# MSP430F155 register map
Vendor: msp430gen; File version: v0.4.0-18-g1912f3a
Registers are 8-bit, read-write, reset 0x0 unless marked. A register's access mark holds for its fields unless they carry their own. Offsets are from the block's base; [hi:lo] are bit positions; {n}, {i} and the like mark numbered series.

## SUPPLY_VOLTAGE_SUPERVISOR
Base 0x00000054
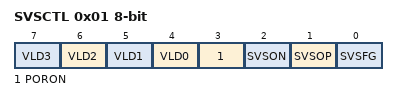
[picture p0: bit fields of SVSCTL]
0x01 SVSCTL — SVS Control
  [n+4] VLD{n} (n=0..3)
  [3] PORON — Enable POR Generation if Low Voltage
  [2] SVSON — Switches the SVS on/off
  [1] SVSOP — SVS output (read only)
  [0] SVSFG — SVS Flag

## SYSTEM_CLOCK
Base 0x00000056
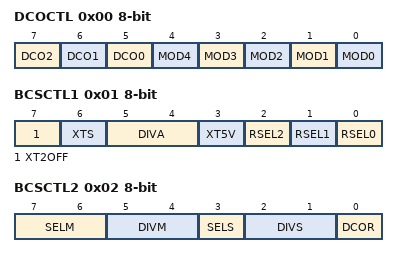
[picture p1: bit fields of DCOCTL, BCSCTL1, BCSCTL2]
0x00 DCOCTL — DCO Clock Frequency Control
  [7] DCO2 — DCO Select Bit 2
  [6] DCO1 — DCO Select Bit 1
  [5] DCO0 — DCO Select Bit 0
  [n] MOD{n} (n=0..4) — Modulation Bit {n}
0x01 BCSCTL1 — Basic Clock System Control 1
  [7] XT2OFF — Enable XT2CLK
  [6] XTS — LFXTCLK 0:Low Freq. / 1: High Freq.
  [5:4] DIVA — ACLK Divider 0
    0=ACLK Divider 0: /1; 1=ACLK Divider 1: /2; 2=ACLK Divider 2: /4; 3=ACLK Divider 3: /8
  [3] XT5V — XT5V should always be reset
  [2] RSEL2 — Range Select Bit 2
  [1] RSEL1 — Range Select Bit 1
  [0] RSEL0 — Range Select Bit 0
0x02 BCSCTL2 — Basic Clock System Control 2
  [7:6] SELM — MCLK Source Select 0
    0=MCLK Source Select 0: DCOCLK; 1=MCLK Source Select 1: DCOCLK; 2=MCLK Source Select 2: XT2CLK/LFXTCLK; 3=MCLK Source Select 3: LFXTCLK
  [5:4] DIVM — MCLK Divider 0
    0=MCLK Divider 0: /1; 1=MCLK Divider 1: /2; 2=MCLK Divider 2: /4; 3=MCLK Divider 3: /8
  [3] SELS — SMCLK Source Select 0:DCOCLK / 1:XT2CLK/LFXTCLK
  [2:1] DIVS — SMCLK Divider 0
    0=SMCLK Divider 0: /1; 1=SMCLK Divider 1: /2; 2=SMCLK Divider 2: /4; 3=SMCLK Divider 3: /8
  [0] DCOR — Enable External Resistor : 1

## COMPARATOR_A
Base 0x00000058
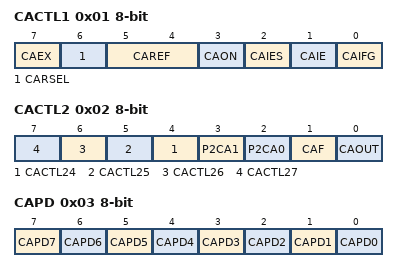
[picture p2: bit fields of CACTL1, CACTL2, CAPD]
0x01 CACTL1 — Comparator A Control 1
  [7] CAEX — Comp. A Exchange Inputs
  [6] CARSEL — Comp. A Internal Reference Enable
  [5:4] CAREF — Comp. A Internal Reference Select 0
    0=Comp. A Int. Ref. Select 0 : Off; 1=Comp. A Int. Ref. Select 1 : 0.25*Vcc; 2=Comp. A Int. Ref. Select 2 : 0.5*Vcc; 3=Comp. A Int. Ref. Select 3 : Vt
  [3] CAON — Comp. A enable
  [2] CAIES — Comp. A Int. Edge Select: 0:rising / 1:falling
  [1] CAIE — Comp. A Interrupt Enable
  [0] CAIFG — Comp. A Interrupt Flag
0x02 CACTL2 — Comparator A Control 2
  [n-20] CACTL{n} (n=24..27)
  [3] P2CA1 — Comp. A Connect External Signal to CA1 : 1
  [2] P2CA0 — Comp. A Connect External Signal to CA0 : 1
  [1] CAF — Comp. A Enable Output Filter
  [0] CAOUT — Comp. A Output
0x03 CAPD — Comparator A Port Disable
  [7] CAPD7 — Comp. A Disable Input Buffer of Port Register .7
  [6] CAPD6 — Comp. A Disable Input Buffer of Port Register .6
  [5] CAPD5 — Comp. A Disable Input Buffer of Port Register .5
  [4] CAPD4 — Comp. A Disable Input Buffer of Port Register .4
  [3] CAPD3 — Comp. A Disable Input Buffer of Port Register .3
  [2] CAPD2 — Comp. A Disable Input Buffer of Port Register .2
  [1] CAPD1 — Comp. A Disable Input Buffer of Port Register .1
  [0] CAPD0 — Comp. A Disable Input Buffer of Port Register .0

## USART_0_UART_SPI_MODE
Base 0x00000070
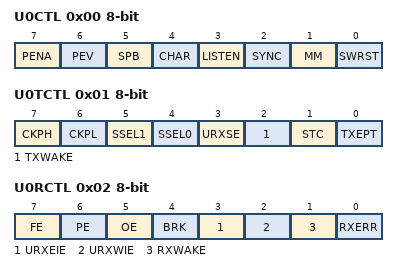
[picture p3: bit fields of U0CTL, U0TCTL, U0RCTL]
0x00 U0CTL — USART 0 Control
  [7] PENA — Parity enable
  [6] PEV — Parity 0:odd / 1:even
  [5] SPB — Stop Bits 0:one / 1: two
  [4] CHAR — Data 0:7-bits / 1:8-bits
  [3] LISTEN — Listen mode
  [2] SYNC — UART / SPI mode
  [1] MM — Master Mode off/on
  [0] SWRST — USART Software Reset
0x01 U0TCTL — USART 0 Transmit Control
  [7] CKPH — SPI: Clock Phase
  [6] CKPL — Clock Polarity
  [5] SSEL1 — Clock Source Select 1
  [4] SSEL0 — Clock Source Select 0
  [3] URXSE — Receive Start edge select
  [2] TXWAKE — TX Wake up mode
  [1] STC — SPI: STC enable 0:on / 1:off
  [0] TXEPT — TX Buffer empty
0x02 U0RCTL — USART 0 Receive Control
  [7] FE — Frame Error
  [6] PE — Parity Error
  [5] OE — Overrun Error
  [4] BRK — Break detected
  [3] URXEIE — RX Error interrupt enable
  [2] URXWIE — RX Wake up interrupt enable
  [1] RXWAKE — RX Wake up detect
  [0] RXERR — RX Error Error
0x03 U0MCTL — USART 0 Modulation Control
0x04 U0BR0 — USART 0 Baud Rate 0
0x05 U0BR1 — USART 0 Baud Rate 1
0x06 U0RXBUF — USART 0 Receive Buffer
0x07 U0TXBUF — USART 0 Transmit Buffer
